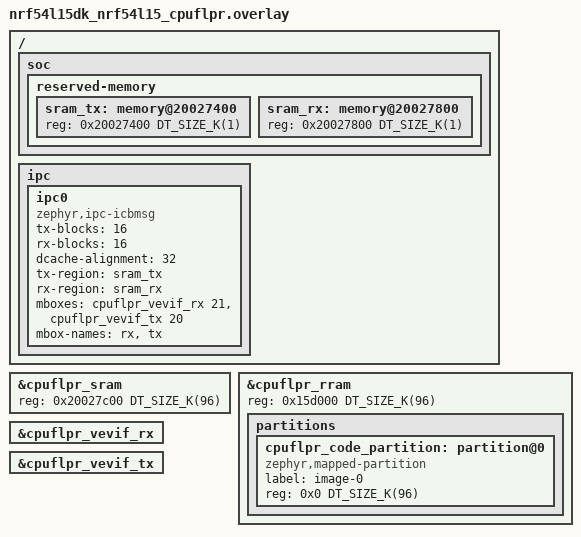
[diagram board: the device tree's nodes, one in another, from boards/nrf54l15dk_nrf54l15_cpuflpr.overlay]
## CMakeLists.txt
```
#
# Copyright (c) 2026 Nordic Semiconductor ASA
#
# SPDX-License-Identifier: Apache-2.0
#

cmake_minimum_required(VERSION 3.28.0)
find_package(Zephyr REQUIRED HINTS $ENV{ZEPHYR_BASE})

project(shell_remote_test_remote)

target_sources(app PRIVATE src/main.c)
```

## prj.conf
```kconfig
CONFIG_IPC_SERVICE=y
CONFIG_MBOX=y
#CONFIG_ASSERT=y

CONFIG_SHELL=y
CONFIG_SHELL_REMOTE_CLI=y
CONFIG_SHELL_BACKEND_SERIAL=n
CONFIG_SHELL_REMOTE_CLI_BUF_SIZE=128

CONFIG_BOOT_BANNER=n
CONFIG_GPIO=n
#CONFIG_LOG=y
#CONFIG_LOG_PRINTK=n
#CONFIG_LOG_MODE_MINIMAL=y
CONFIG_SERIAL=n
CONFIG_CONSOLE=n
CONFIG_UART_CONSOLE=n
CONFIG_PRINTK=n
```

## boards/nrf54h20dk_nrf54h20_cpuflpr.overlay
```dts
/*
 * Copyright (c) 2026 Nordic Semiconductor ASA
 *
 * SPDX-License-Identifier: Apache-2.0
 */

&cpuflpr_vevif {
	status = "okay";
};

&cpuapp_bellboard {
	status = "okay";
};

ipc0: &cpuapp_cpuflpr_ipc {
	status = "okay";
};

&uart120 {
	status = "disabled";
};
```

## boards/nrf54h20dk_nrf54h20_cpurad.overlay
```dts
/*
 * Copyright (c) 2026 Nordic Semiconductor ASA
 *
 * SPDX-License-Identifier: Apache-2.0
 *
 * Console UART is unused (remote shell uses IPC only); disable the node and
 * drop chosen references so the disabled UART is not selected as console.
 */

/ {
	chosen {
		/delete-property/ zephyr,console;
		/delete-property/ zephyr,shell-uart;
		/delete-property/ zephyr,uart-mcumgr;
	};
};

&uart135 {
	status = "disabled";
};
```

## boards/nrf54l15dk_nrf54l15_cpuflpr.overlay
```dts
/*
 * Copyright (c) 2026 Nordic Semiconductor ASA
 *
 * SPDX-License-Identifier: Apache-2.0
 */

/ {
	soc {
		reserved-memory {
			#address-cells = <1>;
			#size-cells = <1>;

			sram_tx: memory@20027400 {
				reg = <0x20027400 DT_SIZE_K(1)>;
			};

			sram_rx: memory@20027800 {
				reg = <0x20027800 DT_SIZE_K(1)>;
			};
		};
	};

	ipc {
		ipc0: ipc0 {
			compatible = "zephyr,ipc-icbmsg";
			tx-blocks = <16>;
			rx-blocks = <16>;
			dcache-alignment = <32>;
			tx-region = <&sram_tx>;
			rx-region = <&sram_rx>;
			mboxes = <&cpuflpr_vevif_rx 21>, <&cpuflpr_vevif_tx 20>;
			mbox-names = "rx", "tx";
			status = "okay";
		};
	};
};

&cpuflpr_sram {
	reg = <0x20027c00 DT_SIZE_K(96)>;
	ranges = <0x0 0x20027c00 DT_SIZE_K(96)>;
};

&cpuflpr_rram {
	reg = <0x15d000 DT_SIZE_K(96)>;
	ranges = <0x0 0x15d000 DT_SIZE_K(96)>;

	partitions {
		#address-cells = <1>;
		#size-cells = <1>;
		ranges;

		cpuflpr_code_partition: partition@0 {
			compatible = "zephyr,mapped-partition";
			label = "image-0";
			reg = <0x0 DT_SIZE_K(96)>;
		};
	};
};

&cpuflpr_vevif_rx {
	status = "okay";
};

&cpuflpr_vevif_tx {
	status = "okay";
};
```

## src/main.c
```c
/*
 * Copyright (c) 2026 Nordic Semiconductor ASA
 *
 * SPDX-License-Identifier: Apache-2.0
 */

#include <zephyr/kernel.h>
#include <zephyr/shell/shell.h>
#include <zephyr/sys/util.h>
#include <zephyr/logging/log_ctrl.h>
#include <zephyr/shell/shell_remote_cli.h>
#include <string.h>

/* Sorted alphabetically for dynamic command completion (see shell_dynamic_get). */
static const char *const dyn_subcmd_names[] = {
	"sub_cmd_0",
	"sub_cmd_1",
	"sub_cmd_2",
};

static void dyn_subcmd_get(size_t idx, struct shell_static_entry *entry)
{
	if (idx < ARRAY_SIZE(dyn_subcmd_names)) {
		entry->syntax = dyn_subcmd_names[idx];
		entry->handler = NULL;
		entry->subcmd = NULL;
		entry->help = "Print this subcommand name";
	} else {
		entry->syntax = NULL;
	}
}

static int cmd_dyn_parent(const struct shell *sh, size_t argc, char **argv)
{
	if (argc < 2) {
		shell_error(sh, "Missing subcommand");
		return -EINVAL;
	}

	shell_print(sh, "%s", argv[1]);
	return 0;
}

SHELL_DYNAMIC_CMD_CREATE(m_sub_dyn_cmd, dyn_subcmd_get);
SHELL_CMD_REGISTER(dyn_cmd, &m_sub_dyn_cmd, "Command with dynamic subcommands", cmd_dyn_parent);

static int cmd_ping(const struct shell *sh, size_t argc, char **argv)
{
	ARG_UNUSED(argc);
	ARG_UNUSED(argv);

	shell_print(sh, "pong");
	return 0;
}

SHELL_CMD_REGISTER(ping, NULL, "Basic remote shell command", cmd_ping);

static int cmd1_handler(const struct shell *sh, size_t argc, char **argv)
{
	ARG_UNUSED(argc);
	ARG_UNUSED(argv);
	uint64_t ll = 12345678901234LL;
	uint32_t l = 1234567890;

	shell_print(sh, "cmd1 executed %llu %u", ll, l);

	return 0;
}

static int cmd2_handler(const struct shell *sh, size_t argc, char **argv)
{
	if (argc > 1) {
		shell_print(sh, "cmd2 executed with arg: %s", argv[1]);
	} else {
		shell_print(sh, "cmd2 executed without arg");
	}

	return 0;
}

static int cmd3_handler(const struct shell *sh, size_t argc, char **argv)
{
	ARG_UNUSED(argc);
	ARG_UNUSED(argv);

	shell_error(sh, "remote_static_cmd3_err");
	shell_warn(sh, "remote_static_cmd3_warn");
	return 0;
}

static int too_long_string_cmd_handler(const struct shell *sh, size_t argc, char **argv)
{
	/* Long string on stack that will be added to the package included
	 * in the message. It should not fit in the buffer and error message
	 * shall be sent instead.
	 */
	char long_stack_str[CONFIG_SHELL_REMOTE_CLI_BUF_SIZE];

	ARG_UNUSED(argc);
	ARG_UNUSED(argv);

	memset(long_stack_str, 'x', sizeof(long_stack_str) - 1);
	long_stack_str[sizeof(long_stack_str) - 1] = '\0';

	shell_print(sh, "too_long_string_cmd: %s", long_stack_str);
	return 0;
}

SHELL_SUBCMD_ADD((static_cmd), cmd1, NULL, "help for cmd1", cmd1_handler, 1, 0);
SHELL_SUBCMD_ADD((static_cmd), cmd2, NULL, "help for cmd2", cmd2_handler, 1, 1);
SHELL_SUBCMD_ADD((static_cmd), cmd3, NULL, "help for cmd3", cmd3_handler, 1, 0);
SHELL_SUBCMD_ADD((static_cmd), too_long_string_cmd, NULL, "help for too_long_string_cmd",
		 too_long_string_cmd_handler, 1, 0);

SHELL_SUBCMD_SET_CREATE(multi_static_cmd, (static_cmd));
SHELL_CMD_REGISTER(static_cmd, &multi_static_cmd, "Static command with subcommands", NULL);

int main(void)
{
#ifndef CONFIG_MULTITHREADING
	while (1) {
		shell_remote_cmd_process();
		if (LOG_PROCESS() == false) {
			k_cpu_idle();
		}
	}
#endif
	return 0;
}
```
